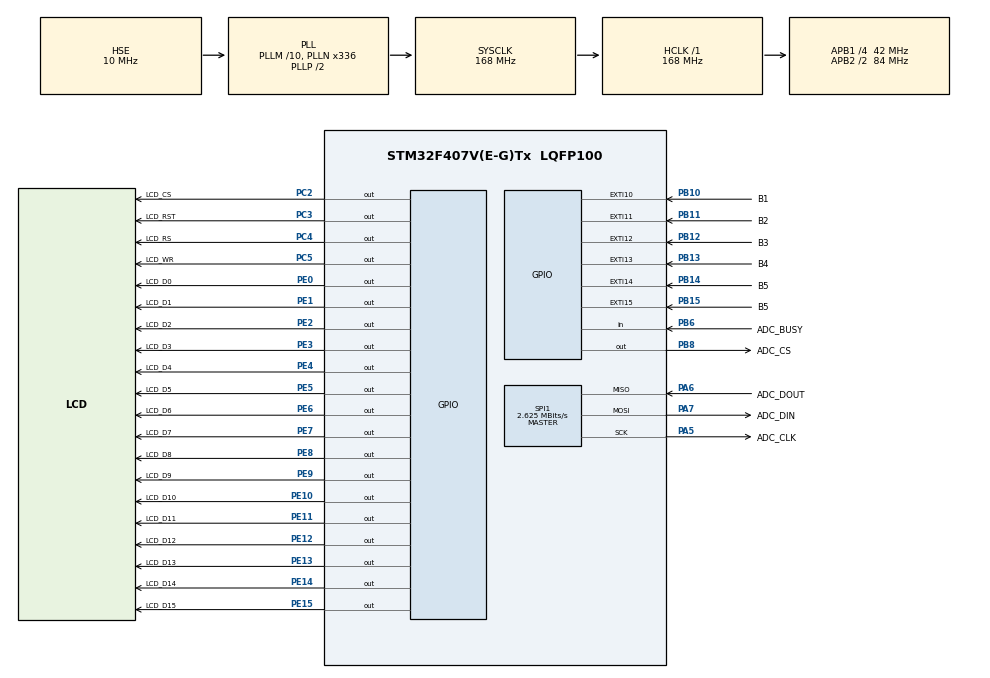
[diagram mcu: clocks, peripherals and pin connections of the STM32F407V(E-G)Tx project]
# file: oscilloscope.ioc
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Dma.Request0=SPI1_TX
Dma.Request1=SPI1_RX
Dma.SPI1_RX.1.Direction=DMA_PERIPH_TO_MEMORY
Dma.SPI1_RX.1.FIFOMode=DMA_FIFOMODE_DISABLE
Dma.SPI1_RX.1.Instance=DMA2_Stream0
Dma.SPI1_RX.1.MemDataAlignment=DMA_MDATAALIGN_BYTE
Dma.SPI1_RX.1.MemInc=DMA_MINC_ENABLE
Dma.SPI1_RX.1.Mode=DMA_CIRCULAR
Dma.SPI1_RX.1.PeriphDataAlignment=DMA_PDATAALIGN_BYTE
Dma.SPI1_RX.1.PeriphInc=DMA_PINC_DISABLE
Dma.SPI1_RX.1.Priority=DMA_PRIORITY_LOW
Dma.SPI1_TX.0.Direction=DMA_MEMORY_TO_PERIPH
Dma.SPI1_TX.0.FIFOMode=DMA_FIFOMODE_DISABLE
Dma.SPI1_TX.0.Instance=DMA2_Stream3
Dma.SPI1_TX.0.MemDataAlignment=DMA_MDATAALIGN_BYTE
Dma.SPI1_TX.0.MemInc=DMA_MINC_ENABLE
Dma.SPI1_TX.0.Mode=DMA_CIRCULAR
Dma.SPI1_TX.0.PeriphDataAlignment=DMA_PDATAALIGN_BYTE
Dma.SPI1_TX.0.PeriphInc=DMA_PINC_DISABLE
Dma.SPI1_TX.0.Priority=DMA_PRIORITY_LOW
Mcu.Family=STM32F4
Mcu.Name=STM32F407V(E-G)Tx
Mcu.Package=LQFP100
NVIC.DMA2_Stream0_IRQn=true\:0\:0\:false\:false\:true\:false\:true
NVIC.DMA2_Stream3_IRQn=true\:0\:0\:false\:false\:true\:false\:true
NVIC.EXTI15_10_IRQn=true\:0\:0\:false\:false\:true\:true\:true
NVIC.PriorityGroup=NVIC_PRIORITYGROUP_4
NVIC.SPI1_IRQn=true\:2\:0\:true\:false\:true\:true\:true
NVIC.TIM2_IRQn=true\:1\:0\:true\:true\:true\:1\:true\:true
PA5.GPIO_Label=ADC_CLK
PA5.Mode=Full_Duplex_Master
PA5.Signal=SPI1_SCK
PA6.GPIO_Label=ADC_DOUT
PA6.Mode=Full_Duplex_Master
PA6.Signal=SPI1_MISO
PA7.GPIO_Label=ADC_DIN
PA7.Mode=Full_Duplex_Master
PA7.Signal=SPI1_MOSI
PB10.GPIO_Label=B1
PB10.GPIO_ModeDefaultEXTI=GPIO_MODE_IT_RISING_FALLING
PB10.GPIO_PuPd=GPIO_PULLUP
PB10.Signal=GPXTI10
PB11.GPIO_Label=B2
PB11.GPIO_ModeDefaultEXTI=GPIO_MODE_IT_RISING_FALLING
PB11.GPIO_PuPd=GPIO_PULLUP
PB11.Signal=GPXTI11
PB12.GPIO_Label=B3
PB12.GPIO_PuPd=GPIO_PULLUP
PB12.Signal=GPXTI12
PB13.GPIO_Label=B4
PB13.GPIO_PuPd=GPIO_PULLUP
PB13.Signal=GPXTI13
PB14.GPIO_Label=B5
PB14.GPIO_PuPd=GPIO_PULLUP
PB14.Signal=GPXTI14
PB15.GPIO_Label=B5
PB15.GPIO_PuPd=GPIO_PULLUP
PB15.Signal=GPXTI15
PB6.GPIO_Label=ADC_BUSY
PB6.Signal=GPIO_Input
PB8.GPIO_Label=ADC_CS
PB8.GPIO_ModeDefaultOutputPP=GPIO_MODE_OUTPUT_PP
PB8.PinState=GPIO_PIN_SET
PB8.Signal=GPIO_Output
PC2.GPIO_Label=LCD_CS
PC2.Signal=GPIO_Output
PC3.GPIO_Label=LCD_RST
PC3.Signal=GPIO_Output
PC4.GPIO_Label=LCD_RS
PC4.Signal=GPIO_Output
PC5.GPIO_Label=LCD_WR
PC5.Signal=GPIO_Output
PE0.GPIO_Label=LCD_D0
PE0.GPIO_Speed=GPIO_SPEED_FREQ_LOW
PE0.Signal=GPIO_Output
PE1.GPIO_Label=LCD_D1
PE1.GPIO_Speed=GPIO_SPEED_FREQ_LOW
PE1.Signal=GPIO_Output
PE10.GPIO_Label=LCD_D10
PE10.GPIO_Speed=GPIO_SPEED_FREQ_VERY_HIGH
PE10.Signal=GPIO_Output
PE11.GPIO_Label=LCD_D11
PE11.GPIO_Speed=GPIO_SPEED_FREQ_VERY_HIGH
PE11.Signal=GPIO_Output
PE12.GPIO_Label=LCD_D12
PE12.GPIO_Speed=GPIO_SPEED_FREQ_VERY_HIGH
PE12.Signal=GPIO_Output
PE13.GPIO_Label=LCD_D13
PE13.GPIO_Speed=GPIO_SPEED_FREQ_VERY_HIGH
PE13.Signal=GPIO_Output
PE14.GPIO_Label=LCD_D14
PE14.GPIO_Speed=GPIO_SPEED_FREQ_VERY_HIGH
PE14.Signal=GPIO_Output
PE15.GPIO_Label=LCD_D15
PE15.GPIO_Speed=GPIO_SPEED_FREQ_VERY_HIGH
PE15.Signal=GPIO_Output
PE2.GPIO_Label=LCD_D2
PE2.GPIO_Speed=GPIO_SPEED_FREQ_LOW
PE2.Signal=GPIO_Output
PE3.GPIO_Label=LCD_D3
PE3.GPIO_Speed=GPIO_SPEED_FREQ_LOW
PE3.Signal=GPIO_Output
PE4.GPIO_Label=LCD_D4
PE4.GPIO_Speed=GPIO_SPEED_FREQ_LOW
PE4.Signal=GPIO_Output
PE5.GPIO_Label=LCD_D5
PE5.GPIO_Speed=GPIO_SPEED_FREQ_LOW
PE5.Signal=GPIO_Output
PE6.GPIO_Label=LCD_D6
PE6.GPIO_Speed=GPIO_SPEED_FREQ_LOW
PE6.Signal=GPIO_Output
PE7.GPIO_Label=LCD_D7
PE7.GPIO_Speed=GPIO_SPEED_FREQ_LOW
PE7.Signal=GPIO_Output
PE8.GPIO_Label=LCD_D8
PE8.GPIO_Speed=GPIO_SPEED_FREQ_VERY_HIGH
PE8.Signal=GPIO_Output
PE9.GPIO_Label=LCD_D9
PE9.GPIO_Speed=GPIO_SPEED_FREQ_VERY_HIGH
PE9.Signal=GPIO_Output
PH0-OSC_IN.Mode=HSE-External-Oscillator
PH0-OSC_IN.Signal=RCC_OSC_IN
PH1-OSC_OUT.Mode=HSE-External-Oscillator
PH1-OSC_OUT.Signal=RCC_OSC_OUT
ProjectManager.HeapSize=0x200
ProjectManager.StackSize=0x400
ProjectManager.TargetToolchain=STM32CubeIDE
RCC.48MHZClocksFreq_Value=84000000
RCC.AHBFreq_Value=168000000
RCC.APB1CLKDivider=RCC_HCLK_DIV4
RCC.APB1Freq_Value=42000000
RCC.APB1TimFreq_Value=84000000
RCC.APB2CLKDivider=RCC_HCLK_DIV2
RCC.APB2Freq_Value=84000000
RCC.APB2TimFreq_Value=168000000
RCC.CortexFreq_Value=168000000
RCC.HCLKFreq_Value=168000000
RCC.HSE_VALUE=10000000
RCC.HSI_VALUE=16000000
RCC.LSE_VALUE=32768
RCC.PLLM=10
RCC.PLLN=336
RCC.PLLSourceVirtual=RCC_PLLSOURCE_HSE
RCC.SYSCLKFreq_VALUE=168000000
RCC.SYSCLKSource=RCC_SYSCLKSOURCE_PLLCLK
RCC.VCOOutputFreq_Value=336000000
SPI1.BaudRatePrescaler=SPI_BAUDRATEPRESCALER_32
SPI1.CalculateBaudRate=2.625 MBits/s
SPI1.Direction=SPI_DIRECTION_2LINES
SPI1.Mode=SPI_MODE_MASTER
SPI1.VirtualType=VM_MASTER
TIM2.Period=1680000
VP_TIM2_VS_ClockSourceINT.Mode=Internal
board=custom

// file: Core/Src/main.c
/* USER CODE BEGIN Header */
/**
  ******************************************************************************
  * @file           : main.c
  * @brief          : Main program body
  ******************************************************************************
  * @attention
  *
  * <h2><center>&copy; Copyright (c) 2022 STMicroelectronics.
  * All rights reserved.</center></h2>
  *
  * This software component is licensed by ST under BSD 3-Clause license,
  * the "License"; You may not use this file except in compliance with the
  * License. You may obtain a copy of the License at:
  *                        opensource.org/licenses/BSD-3-Clause
  *
  ******************************************************************************
  */
/* USER CODE END Header */
#include "main.h"
#include "dma.h"
#include "spi.h"
#include "tim.h"
#include "gpio.h"

/* USER CODE BEGIN Includes */
#include "app.h"
/* USER CODE END Includes */

void SystemClock_Config(void);
static void MX_NVIC_Init(void);

int main(void)
{

  /* MCU Configuration--------------------------------------------------------*/

  /* Reset of all peripherals, Initializes the Flash interface and the Systick. */
  HAL_Init();

  /* Configure the system clock */
  SystemClock_Config();

  /* Initialize all configured peripherals */
  MX_GPIO_Init();
  MX_SPI1_Init();
  MX_DMA_Init();
  MX_TIM2_Init();

  /* Initialize interrupts */
  MX_NVIC_Init();
  /* USER CODE BEGIN 2 */
  userCode2();
  /* USER CODE END 2 */

  /* Infinite loop */
  /* USER CODE BEGIN WHILE */
  while (1)
  {
	  userCodeWhile();
    /* USER CODE END WHILE */

  }
}

void SystemClock_Config(void)
{
  RCC_OscInitTypeDef RCC_OscInitStruct = {0};
  RCC_ClkInitTypeDef RCC_ClkInitStruct = {0};

  /** Configure the main internal regulator output voltage
  */
  __HAL_RCC_PWR_CLK_ENABLE();
  __HAL_PWR_VOLTAGESCALING_CONFIG(PWR_REGULATOR_VOLTAGE_SCALE1);
  /** Initializes the RCC Oscillators according to the specified parameters
  * in the RCC_OscInitTypeDef structure.
  */
  RCC_OscInitStruct.OscillatorType = RCC_OSCILLATORTYPE_HSE;
  RCC_OscInitStruct.HSEState = RCC_HSE_ON;
  RCC_OscInitStruct.PLL.PLLState = RCC_PLL_ON;
  RCC_OscInitStruct.PLL.PLLSource = RCC_PLLSOURCE_HSE;
  RCC_OscInitStruct.PLL.PLLM = 10;
  RCC_OscInitStruct.PLL.PLLN = 336;
  RCC_OscInitStruct.PLL.PLLP = RCC_PLLP_DIV2;
  RCC_OscInitStruct.PLL.PLLQ = 4;
  if (HAL_RCC_OscConfig(&RCC_OscInitStruct) != HAL_OK)
  {
    Error_Handler();
  }
  /** Initializes the CPU, AHB and APB buses clocks
  */
  RCC_ClkInitStruct.ClockType = RCC_CLOCKTYPE_HCLK|RCC_CLOCKTYPE_SYSCLK
                              |RCC_CLOCKTYPE_PCLK1|RCC_CLOCKTYPE_PCLK2;
  RCC_ClkInitStruct.SYSCLKSource = RCC_SYSCLKSOURCE_PLLCLK;
  RCC_ClkInitStruct.AHBCLKDivider = RCC_SYSCLK_DIV1;
  RCC_ClkInitStruct.APB1CLKDivider = RCC_HCLK_DIV4;
  RCC_ClkInitStruct.APB2CLKDivider = RCC_HCLK_DIV2;

  if (HAL_RCC_ClockConfig(&RCC_ClkInitStruct, FLASH_LATENCY_5) != HAL_OK)
  {
    Error_Handler();
  }
}

/**
  * @brief NVIC Configuration.
  * @retval None
  */
static void MX_NVIC_Init(void)
{
  /* TIM2_IRQn interrupt configuration */
  HAL_NVIC_SetPriority(TIM2_IRQn, 1, 0);
  HAL_NVIC_EnableIRQ(TIM2_IRQn);
}

void Error_Handler(void)
{
  __disable_irq();
  while (1)
  {
  }
}

/************************ (C) COPYRIGHT STMicroelectronics *****END OF FILE****/
